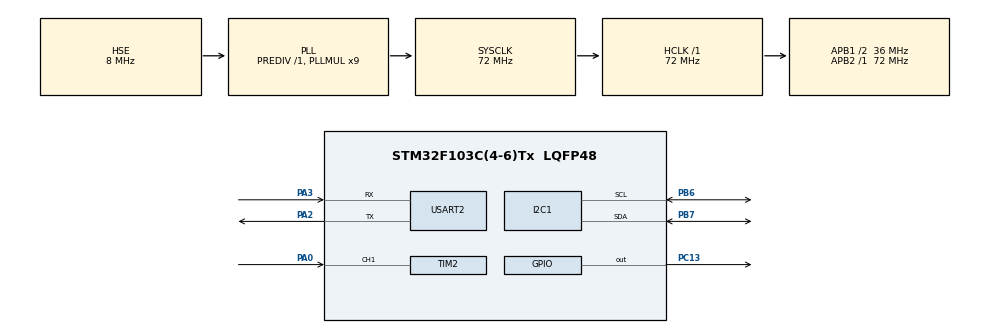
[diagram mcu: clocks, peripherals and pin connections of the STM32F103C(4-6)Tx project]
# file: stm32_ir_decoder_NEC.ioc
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Dma.Request0=TIM2_CH1
Dma.Request1=USART2_TX
Dma.Request2=USART2_RX
Dma.TIM2_CH1.0.Direction=DMA_PERIPH_TO_MEMORY
Dma.TIM2_CH1.0.Instance=DMA1_Channel5
Dma.TIM2_CH1.0.MemDataAlignment=DMA_MDATAALIGN_HALFWORD
Dma.TIM2_CH1.0.MemInc=DMA_MINC_ENABLE
Dma.TIM2_CH1.0.Mode=DMA_NORMAL
Dma.TIM2_CH1.0.PeriphDataAlignment=DMA_PDATAALIGN_HALFWORD
Dma.TIM2_CH1.0.PeriphInc=DMA_PINC_DISABLE
Dma.TIM2_CH1.0.Priority=DMA_PRIORITY_LOW
Dma.USART2_RX.2.Direction=DMA_PERIPH_TO_MEMORY
Dma.USART2_RX.2.Instance=DMA1_Channel6
Dma.USART2_RX.2.MemDataAlignment=DMA_MDATAALIGN_BYTE
Dma.USART2_RX.2.MemInc=DMA_MINC_ENABLE
Dma.USART2_RX.2.Mode=DMA_NORMAL
Dma.USART2_RX.2.PeriphDataAlignment=DMA_PDATAALIGN_BYTE
Dma.USART2_RX.2.PeriphInc=DMA_PINC_DISABLE
Dma.USART2_RX.2.Priority=DMA_PRIORITY_LOW
Dma.USART2_TX.1.Direction=DMA_MEMORY_TO_PERIPH
Dma.USART2_TX.1.Instance=DMA1_Channel7
Dma.USART2_TX.1.MemDataAlignment=DMA_MDATAALIGN_BYTE
Dma.USART2_TX.1.MemInc=DMA_MINC_ENABLE
Dma.USART2_TX.1.Mode=DMA_NORMAL
Dma.USART2_TX.1.PeriphDataAlignment=DMA_PDATAALIGN_BYTE
Dma.USART2_TX.1.PeriphInc=DMA_PINC_DISABLE
Dma.USART2_TX.1.Priority=DMA_PRIORITY_LOW
I2C1.I2C_Mode=I2C_Fast
Mcu.Family=STM32F1
Mcu.Name=STM32F103C(4-6)Tx
Mcu.Package=LQFP48
NVIC.DMA1_Channel5_IRQn=true\:0\:0\:false\:false\:true\:false\:true\:true
NVIC.DMA1_Channel6_IRQn=true\:0\:0\:false\:false\:true\:false\:true\:true
NVIC.DMA1_Channel7_IRQn=true\:0\:0\:false\:false\:true\:false\:true\:true
NVIC.PriorityGroup=NVIC_PRIORITYGROUP_4
PA0-WKUP.Signal=S_TIM2_CH1_ETR
PA13.Mode=Serial_Wire
PA13.Signal=SYS_JTMS-SWDIO
PA14.Mode=Serial_Wire
PA14.Signal=SYS_JTCK-SWCLK
PA2.Mode=Asynchronous
PA2.Signal=USART2_TX
PA3.Mode=Asynchronous
PA3.Signal=USART2_RX
PB6.GPIO_Pu=GPIO_PULLUP
PB6.Mode=I2C
PB6.Signal=I2C1_SCL
PB7.GPIO_Pu=GPIO_PULLUP
PB7.Mode=I2C
PB7.Signal=I2C1_SDA
PC13-TAMPER-RTC.Signal=GPIO_Output
PD0-OSC_IN.Mode=HSE-External-Oscillator
PD0-OSC_IN.Signal=RCC_OSC_IN
PD1-OSC_OUT.Mode=HSE-External-Oscillator
PD1-OSC_OUT.Signal=RCC_OSC_OUT
ProjectManager.HeapSize=0x200
ProjectManager.StackSize=0x400
ProjectManager.TargetToolchain=STM32CubeIDE
RCC.AHBFreq_Value=72000000
RCC.APB1CLKDivider=RCC_HCLK_DIV2
RCC.APB1Freq_Value=36000000
RCC.APB1TimFreq_Value=72000000
RCC.APB2Freq_Value=72000000
RCC.APB2TimFreq_Value=72000000
RCC.HCLKFreq_Value=72000000
RCC.PLLMUL=RCC_PLL_MUL9
RCC.PLLSourceVirtual=RCC_PLLSOURCE_HSE
RCC.SYSCLKFreq_VALUE=72000000
RCC.SYSCLKSource=RCC_SYSCLKSOURCE_PLLCLK
RCC.USBFreq_Value=72000000
SH.S_TIM2_CH1_ETR.0=TIM2_CH1,Input_Capture1_from_TI1
SH.S_TIM2_CH1_ETR.1=TIM2_CH1,TriggerSource_TI1FP1
TIM2.Channel-Input_Capture1_from_TI1=TIM_CHANNEL_1
TIM2.ICFilter_CH1=4
TIM2.ICPolarity_CH1=TIM_INPUTCHANNELPOLARITY_FALLING
TIM2.Prescaler=72-1
USART2.VirtualMode=VM_ASYNC
VP_TIM2_VS_ClockSourceINT.Mode=Internal
VP_TIM2_VS_ControllerModeReset.Mode=Reset Mode
board=custom

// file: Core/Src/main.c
/* USER CODE BEGIN Header */
/**
  ******************************************************************************
  * @file           : main.c
  * @brief          : Main program body
  ******************************************************************************
  * @attention
  *
  * Copyright (c) 2023 STMicroelectronics.
  * All rights reserved.
  *
  * This software is licensed under terms that can be found in the LICENSE file
  * in the root directory of this software component.
  * If no LICENSE file comes with this software, it is provided AS-IS.
  *
  ******************************************************************************
  */
/* USER CODE END Header */
#include "main.h"

/* USER CODE BEGIN Includes */
#include "Application.h"
/* USER CODE END Includes */

I2C_HandleTypeDef hi2c1;

TIM_HandleTypeDef htim2;
DMA_HandleTypeDef hdma_tim2_ch1;

UART_HandleTypeDef huart2;
DMA_HandleTypeDef hdma_usart2_tx;
DMA_HandleTypeDef hdma_usart2_rx;

void SystemClock_Config(void);
static void MX_GPIO_Init(void);
static void MX_DMA_Init(void);
static void MX_TIM2_Init(void);
static void MX_USART2_UART_Init(void);
static void MX_I2C1_Init(void);

/* USER CODE BEGIN 0 */
int _write(int file, char* p, int len){
	HAL_UART_Transmit(&huart2, p, len, 10);
	return len;
}
/* USER CODE END 0 */

int main(void)
{

  /* MCU Configuration--------------------------------------------------------*/

  /* Reset of all peripherals, Initializes the Flash interface and the Systick. */
  HAL_Init();

  /* Configure the system clock */
  SystemClock_Config();

  /* Initialize all configured peripherals */
  MX_GPIO_Init();
  MX_DMA_Init();
  MX_TIM2_Init();
  MX_USART2_UART_Init();
  MX_I2C1_Init();
  /* USER CODE BEGIN 2 */
  Application();
  /* USER CODE END 2 */

  /* Infinite loop */
  while (1)
  {

  }
}

void SystemClock_Config(void)
{
  RCC_OscInitTypeDef RCC_OscInitStruct = {0};
  RCC_ClkInitTypeDef RCC_ClkInitStruct = {0};

  /** Initializes the RCC Oscillators according to the specified parameters
  * in the RCC_OscInitTypeDef structure.
  */
  RCC_OscInitStruct.OscillatorType = RCC_OSCILLATORTYPE_HSE;
  RCC_OscInitStruct.HSEState = RCC_HSE_ON;
  RCC_OscInitStruct.HSEPredivValue = RCC_HSE_PREDIV_DIV1;
  RCC_OscInitStruct.HSIState = RCC_HSI_ON;
  RCC_OscInitStruct.PLL.PLLState = RCC_PLL_ON;
  RCC_OscInitStruct.PLL.PLLSource = RCC_PLLSOURCE_HSE;
  RCC_OscInitStruct.PLL.PLLMUL = RCC_PLL_MUL9;
  if (HAL_RCC_OscConfig(&RCC_OscInitStruct) != HAL_OK)
  {
    Error_Handler();
  }

  /** Initializes the CPU, AHB and APB buses clocks
  */
  RCC_ClkInitStruct.ClockType = RCC_CLOCKTYPE_HCLK|RCC_CLOCKTYPE_SYSCLK
                              |RCC_CLOCKTYPE_PCLK1|RCC_CLOCKTYPE_PCLK2;
  RCC_ClkInitStruct.SYSCLKSource = RCC_SYSCLKSOURCE_PLLCLK;
  RCC_ClkInitStruct.AHBCLKDivider = RCC_SYSCLK_DIV1;
  RCC_ClkInitStruct.APB1CLKDivider = RCC_HCLK_DIV2;
  RCC_ClkInitStruct.APB2CLKDivider = RCC_HCLK_DIV1;

  if (HAL_RCC_ClockConfig(&RCC_ClkInitStruct, FLASH_LATENCY_2) != HAL_OK)
  {
    Error_Handler();
  }
}

static void MX_I2C1_Init(void)
{

  hi2c1.Instance = I2C1;
  hi2c1.Init.ClockSpeed = 400000;
  hi2c1.Init.DutyCycle = I2C_DUTYCYCLE_2;
  hi2c1.Init.OwnAddress1 = 0;
  hi2c1.Init.AddressingMode = I2C_ADDRESSINGMODE_7BIT;
  hi2c1.Init.DualAddressMode = I2C_DUALADDRESS_DISABLE;
  hi2c1.Init.OwnAddress2 = 0;
  hi2c1.Init.GeneralCallMode = I2C_GENERALCALL_DISABLE;
  hi2c1.Init.NoStretchMode = I2C_NOSTRETCH_DISABLE;
  if (HAL_I2C_Init(&hi2c1) != HAL_OK)
  {
    Error_Handler();
  }

}

static void MX_TIM2_Init(void)
{

  TIM_ClockConfigTypeDef sClockSourceConfig = {0};
  TIM_SlaveConfigTypeDef sSlaveConfig = {0};
  TIM_MasterConfigTypeDef sMasterConfig = {0};
  TIM_IC_InitTypeDef sConfigIC = {0};

  htim2.Instance = TIM2;
  htim2.Init.Prescaler = 72-1;
  htim2.Init.CounterMode = TIM_COUNTERMODE_UP;
  htim2.Init.Period = 65535;
  htim2.Init.ClockDivision = TIM_CLOCKDIVISION_DIV1;
  htim2.Init.AutoReloadPreload = TIM_AUTORELOAD_PRELOAD_DISABLE;
  if (HAL_TIM_Base_Init(&htim2) != HAL_OK)
  {
    Error_Handler();
  }
  sClockSourceConfig.ClockSource = TIM_CLOCKSOURCE_INTERNAL;
  if (HAL_TIM_ConfigClockSource(&htim2, &sClockSourceConfig) != HAL_OK)
  {
    Error_Handler();
  }
  if (HAL_TIM_IC_Init(&htim2) != HAL_OK)
  {
    Error_Handler();
  }
  sSlaveConfig.SlaveMode = TIM_SLAVEMODE_RESET;
  sSlaveConfig.InputTrigger = TIM_TS_TI1FP1;
  sSlaveConfig.TriggerPolarity = TIM_INPUTCHANNELPOLARITY_FALLING;
  sSlaveConfig.TriggerFilter = 0;
  if (HAL_TIM_SlaveConfigSynchro(&htim2, &sSlaveConfig) != HAL_OK)
  {
    Error_Handler();
  }
  sMasterConfig.MasterOutputTrigger = TIM_TRGO_RESET;
  sMasterConfig.MasterSlaveMode = TIM_MASTERSLAVEMODE_DISABLE;
  if (HAL_TIMEx_MasterConfigSynchronization(&htim2, &sMasterConfig) != HAL_OK)
  {
    Error_Handler();
  }
  sConfigIC.ICPolarity = TIM_INPUTCHANNELPOLARITY_FALLING;
  sConfigIC.ICSelection = TIM_ICSELECTION_DIRECTTI;
  sConfigIC.ICPrescaler = TIM_ICPSC_DIV1;
  sConfigIC.ICFilter = 4;
  if (HAL_TIM_IC_ConfigChannel(&htim2, &sConfigIC, TIM_CHANNEL_1) != HAL_OK)
  {
    Error_Handler();
  }

}

static void MX_USART2_UART_Init(void)
{

  huart2.Instance = USART2;
  huart2.Init.BaudRate = 115200;
  huart2.Init.WordLength = UART_WORDLENGTH_8B;
  huart2.Init.StopBits = UART_STOPBITS_1;
  huart2.Init.Parity = UART_PARITY_NONE;
  huart2.Init.Mode = UART_MODE_TX_RX;
  huart2.Init.HwFlowCtl = UART_HWCONTROL_NONE;
  huart2.Init.OverSampling = UART_OVERSAMPLING_16;
  if (HAL_UART_Init(&huart2) != HAL_OK)
  {
    Error_Handler();
  }

}

static void MX_DMA_Init(void)
{

  /* DMA controller clock enable */
  __HAL_RCC_DMA1_CLK_ENABLE();

  /* DMA interrupt init */
  /* DMA1_Channel5_IRQn interrupt configuration */
  HAL_NVIC_SetPriority(DMA1_Channel5_IRQn, 0, 0);
  HAL_NVIC_EnableIRQ(DMA1_Channel5_IRQn);
  /* DMA1_Channel6_IRQn interrupt configuration */
  HAL_NVIC_SetPriority(DMA1_Channel6_IRQn, 0, 0);
  HAL_NVIC_EnableIRQ(DMA1_Channel6_IRQn);
  /* DMA1_Channel7_IRQn interrupt configuration */
  HAL_NVIC_SetPriority(DMA1_Channel7_IRQn, 0, 0);
  HAL_NVIC_EnableIRQ(DMA1_Channel7_IRQn);

}

static void MX_GPIO_Init(void)
{
  GPIO_InitTypeDef GPIO_InitStruct = {0};

  /* GPIO Ports Clock Enable */
  __HAL_RCC_GPIOC_CLK_ENABLE();
  __HAL_RCC_GPIOD_CLK_ENABLE();
  __HAL_RCC_GPIOA_CLK_ENABLE();
  __HAL_RCC_GPIOB_CLK_ENABLE();

  /*Configure GPIO pin Output Level */
  HAL_GPIO_WritePin(GPIOC, GPIO_PIN_13, GPIO_PIN_RESET);

  /*Configure GPIO pin : PC13 */
  GPIO_InitStruct.Pin = GPIO_PIN_13;
  GPIO_InitStruct.Mode = GPIO_MODE_OUTPUT_PP;
  GPIO_InitStruct.Pull = GPIO_NOPULL;
  GPIO_InitStruct.Speed = GPIO_SPEED_FREQ_LOW;
  HAL_GPIO_Init(GPIOC, &GPIO_InitStruct);

}

void Error_Handler(void)
{
  __disable_irq();
  while (1)
  {
  }
}
